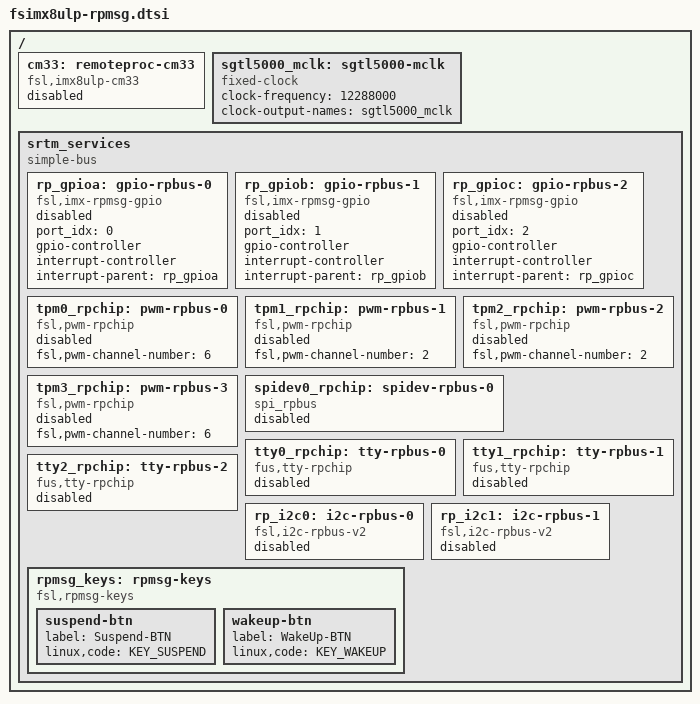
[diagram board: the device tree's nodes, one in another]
// SPDX-License-Identifier: GPL-2.0
/*
* Copyright 2024 F&S Elektronik Systeme GmbH
*
* This program is free software; you can redistribute it and/or modify
* it under the terms of the GNU General Public License version 2 as
* published by the Free Software Foundation.
*
* This program is distributed in the hope that it will be useful,
* but WITHOUT ANY WARRANTY; without even the implied warranty of
* MERCHANTABILITY or FITNESS FOR A PARTICULAR PURPOSE.  See the
* GNU General Public License for more details.
*/

#include <dt-bindings/input/input.h>

/ {

	cm33: remoteproc-cm33 {
		compatible = "fsl,imx8ulp-cm33";
		status = "disabled";
	};

	sgtl5000_mclk: sgtl5000-mclk {
			compatible = "fixed-clock";
			clock-frequency = <12288000>;
			clock-output-names = "sgtl5000_mclk";
			#clock-cells = <0>;
	};

	srtm_services {
		compatible = "simple-bus";
		#address-cells = <1>;
		#size-cells = <0>;

		rp_gpioa: gpio-rpbus-0 {
			compatible = "fsl,imx-rpmsg-gpio";
			port_idx = <0>;
			gpio-controller;
			#gpio-cells = <2>;
			#interrupt-cells = <2>;
			interrupt-controller;
			interrupt-parent = <&rp_gpioa>;
			status = "disabled";
		};

		rp_gpiob: gpio-rpbus-1 {
			compatible = "fsl,imx-rpmsg-gpio";
			port_idx = <1>;
			gpio-controller;
			#gpio-cells = <2>;
			#interrupt-cells = <2>;
			interrupt-controller;
			interrupt-parent = <&rp_gpiob>;
			status = "disabled";
		};

		rp_gpioc: gpio-rpbus-2 {
			compatible = "fsl,imx-rpmsg-gpio";
			port_idx = <2>;
			gpio-controller;
			#gpio-cells = <2>;
			#interrupt-cells = <2>;
			interrupt-controller;
			interrupt-parent = <&rp_gpioc>;
			status = "disabled";
		};

		tpm0_rpchip: pwm-rpbus-0 {
			compatible = "fsl,pwm-rpchip";
			#pwm-cells = <3>;
			fsl,pwm-channel-number = <6>;
			status = "disabled";
		};

		tpm1_rpchip: pwm-rpbus-1 {
			compatible = "fsl,pwm-rpchip";
			#pwm-cells = <3>;
			fsl,pwm-channel-number = <2>;
			status = "disabled";
		};

		tpm2_rpchip: pwm-rpbus-2 {
			compatible = "fsl,pwm-rpchip";
			#pwm-cells = <3>;
			fsl,pwm-channel-number = <2>;
			status = "disabled";
		};

		tpm3_rpchip: pwm-rpbus-3 {
			compatible = "fsl,pwm-rpchip";
			#pwm-cells = <3>;
			fsl,pwm-channel-number = <6>;
			status = "disabled";
		};

		spidev0_rpchip: spidev-rpbus-0 {
			compatible = "spi_rpbus";
			#address-cells = <1>;
			#size-cells = <0>;
			status = "disabled";
		};

		tty0_rpchip: tty-rpbus-0 {
			compatible = "fus,tty-rpchip";
			status = "disabled";
		};

		tty1_rpchip: tty-rpbus-1 {
			compatible = "fus,tty-rpchip";
			status = "disabled";
		};

		tty2_rpchip: tty-rpbus-2 {
			compatible = "fus,tty-rpchip";
			status = "disabled";
		};

		rp_i2c0: i2c-rpbus-0 {
			compatible = "fsl,i2c-rpbus-v2";
			status = "disabled";
		};

		rp_i2c1: i2c-rpbus-1 {
			compatible = "fsl,i2c-rpbus-v2";
			status = "disabled";
        	};

		rpmsg_keys: rpmsg-keys {
			compatible = "fsl,rpmsg-keys";

			suspend-btn {
				label = "Suspend-BTN";
				linux,code = <KEY_SUSPEND>;
			};
			wakeup-btn {
				label = "WakeUp-BTN";
				linux,code = <KEY_WAKEUP>;
			};
		};
	};
};
